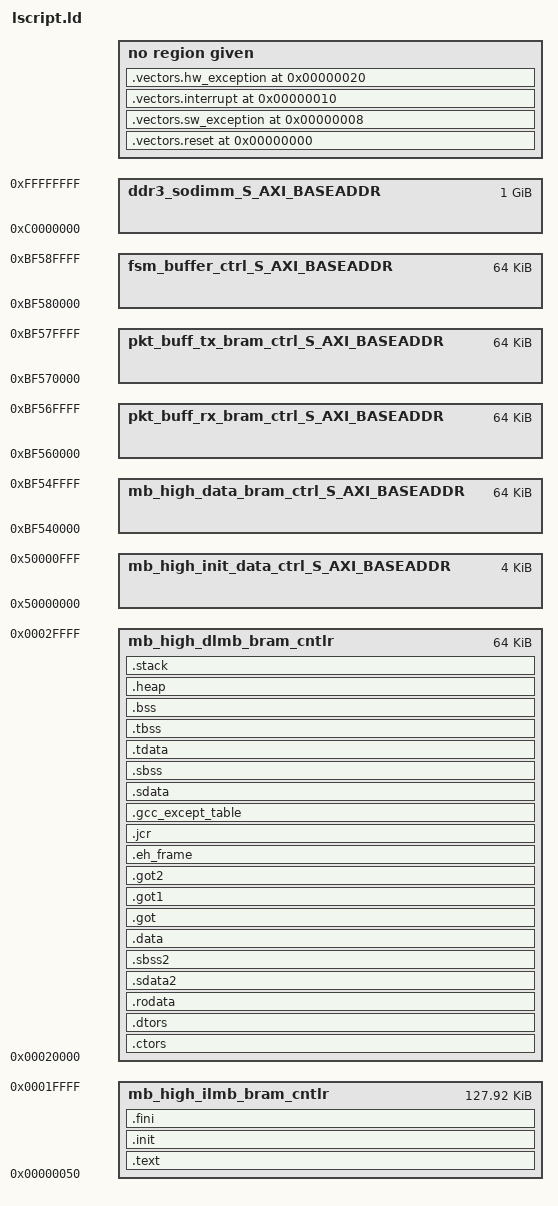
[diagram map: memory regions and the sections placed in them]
/*******************************************************************/
/*                                                                 */
/* This file is automatically generated by linker script generator.*/
/*                                                                 */
/* Version: Xilinx EDK 14.4 EDK_P.49d                                */
/*                                                                 */
/* Copyright (c) 2010 Xilinx, Inc.  All rights reserved.           */
/*                                                                 */
/* Description : MicroBlaze Linker Script                          */
/*                                                                 */
/*******************************************************************/

_STACK_SIZE = DEFINED(_STACK_SIZE) ? _STACK_SIZE : 0x1000;
_HEAP_SIZE = DEFINED(_HEAP_SIZE) ? _HEAP_SIZE : 0x1000;

/* Define Memories in the system */

MEMORY
{
   mb_high_ilmb_bram_cntlr : ORIGIN = 0x00000050, LENGTH = 0x0001FFB0
   mb_high_dlmb_bram_cntlr : ORIGIN = 0x00020000, LENGTH = 0x00010000
   mb_high_init_data_ctrl_S_AXI_BASEADDR : ORIGIN = 0x50000000, LENGTH = 0x00001000
   pkt_buff_tx_bram_ctrl_S_AXI_BASEADDR : ORIGIN = 0xBF570000, LENGTH = 0x00010000
   pkt_buff_rx_bram_ctrl_S_AXI_BASEADDR : ORIGIN = 0xBF560000, LENGTH = 0x00010000
   mb_high_data_bram_ctrl_S_AXI_BASEADDR : ORIGIN = 0xBF540000, LENGTH = 0x00010000
   ddr3_sodimm_S_AXI_BASEADDR : ORIGIN = 0xC0000000, LENGTH = 0x40000000
   fsm_buffer_ctrl_S_AXI_BASEADDR : ORIGIN = 0xBF580000, LENGTH = 0x00010000
}

/* Specify the default entry point to the program */

ENTRY(_start)

/* Define the sections, and where they are mapped in memory */

SECTIONS
{
.vectors.reset 0x00000000 : {
   *(.vectors.reset)
} 

.vectors.sw_exception 0x00000008 : {
   *(.vectors.sw_exception)
} 

.vectors.interrupt 0x00000010 : {
   *(.vectors.interrupt)
} 

.vectors.hw_exception 0x00000020 : {
   *(.vectors.hw_exception)
} 

.text : {
   *(.text)
   *(.text.*)
   *(.gnu.linkonce.t.*)
} > mb_high_ilmb_bram_cntlr

.init : {
   KEEP (*(.init))
} > mb_high_ilmb_bram_cntlr

.fini : {
   KEEP (*(.fini))
} > mb_high_ilmb_bram_cntlr

.ctors : {
   __CTOR_LIST__ = .;
   ___CTORS_LIST___ = .;
   KEEP (*crtbegin.o(.ctors))
   KEEP (*(EXCLUDE_FILE(*crtend.o) .ctors))
   KEEP (*(SORT(.ctors.*)))
   KEEP (*(.ctors))
   __CTOR_END__ = .;
   ___CTORS_END___ = .;
} > mb_high_dlmb_bram_cntlr

.dtors : {
   __DTOR_LIST__ = .;
   ___DTORS_LIST___ = .;
   KEEP (*crtbegin.o(.dtors))
   KEEP (*(EXCLUDE_FILE(*crtend.o) .dtors))
   KEEP (*(SORT(.dtors.*)))
   KEEP (*(.dtors))
   PROVIDE(__DTOR_END__ = .);
   PROVIDE(___DTORS_END___ = .);
} > mb_high_dlmb_bram_cntlr

.rodata : {
   __rodata_start = .;
   *(.rodata)
   *(.rodata.*)
   *(.gnu.linkonce.r.*)
   __rodata_end = .;
} > mb_high_dlmb_bram_cntlr

.sdata2 : {
   . = ALIGN(8);
   __sdata2_start = .;
   *(.sdata2)
   *(.sdata2.*)
   *(.gnu.linkonce.s2.*)
   . = ALIGN(8);
   __sdata2_end = .;
} > mb_high_dlmb_bram_cntlr

.sbss2 : {
   __sbss2_start = .;
   *(.sbss2)
   *(.sbss2.*)
   *(.gnu.linkonce.sb2.*)
   __sbss2_end = .;
} > mb_high_dlmb_bram_cntlr

.data : {
   . = ALIGN(4);
   __data_start = .;
   *(.data)
   *(.data.*)
   *(.gnu.linkonce.d.*)
   __data_end = .;
} > mb_high_dlmb_bram_cntlr

.got : {
   *(.got)
} > mb_high_dlmb_bram_cntlr

.got1 : {
   *(.got1)
} > mb_high_dlmb_bram_cntlr

.got2 : {
   *(.got2)
} > mb_high_dlmb_bram_cntlr

.eh_frame : {
   *(.eh_frame)
} > mb_high_dlmb_bram_cntlr

.jcr : {
   *(.jcr)
} > mb_high_dlmb_bram_cntlr

.gcc_except_table : {
   *(.gcc_except_table)
} > mb_high_dlmb_bram_cntlr

.sdata : {
   . = ALIGN(8);
   __sdata_start = .;
   *(.sdata)
   *(.sdata.*)
   *(.gnu.linkonce.s.*)
   __sdata_end = .;
} > mb_high_dlmb_bram_cntlr

.sbss (NOLOAD) : {
   . = ALIGN(4);
   __sbss_start = .;
   *(.sbss)
   *(.sbss.*)
   *(.gnu.linkonce.sb.*)
   . = ALIGN(8);
   __sbss_end = .;
} > mb_high_dlmb_bram_cntlr

.tdata : {
   __tdata_start = .;
   *(.tdata)
   *(.tdata.*)
   *(.gnu.linkonce.td.*)
   __tdata_end = .;
} > mb_high_dlmb_bram_cntlr

.tbss : {
   __tbss_start = .;
   *(.tbss)
   *(.tbss.*)
   *(.gnu.linkonce.tb.*)
   __tbss_end = .;
} > mb_high_dlmb_bram_cntlr

.bss (NOLOAD) : {
   . = ALIGN(4);
   __bss_start = .;
   *(.bss)
   *(.bss.*)
   *(.gnu.linkonce.b.*)
   *(COMMON)
   . = ALIGN(4);
   __bss_end = .;
} > mb_high_dlmb_bram_cntlr

_SDA_BASE_ = __sdata_start + ((__sbss_end - __sdata_start) / 2 );

_SDA2_BASE_ = __sdata2_start + ((__sbss2_end - __sdata2_start) / 2 );

/* Generate Stack and Heap definitions */

.heap (NOLOAD) : {
   . = ALIGN(8);
   _heap = .;
   _heap_start = .;
   . += _HEAP_SIZE;
   _heap_end = .;
} > mb_high_dlmb_bram_cntlr

.stack (NOLOAD) : {
   _stack_end = .;
   . += _STACK_SIZE;
   . = ALIGN(8);
   _stack = .;
   __stack = _stack;
} > mb_high_dlmb_bram_cntlr

_end = .;
}

